# FM33L0XX register map
File version: 1.0
CPU: SC000 r1p0, little endian, no MPU, no FPU, 3 interrupt priority bits
Registers are 32-bit, read-write, reset 0x0 unless marked. A register's access mark holds for its fields unless they carry their own. Offsets are from the block's base; [hi:lo] are bit positions; {n}, {i} and the like mark numbered series.

## LCD — LCD Registers
Base 0x40010C00
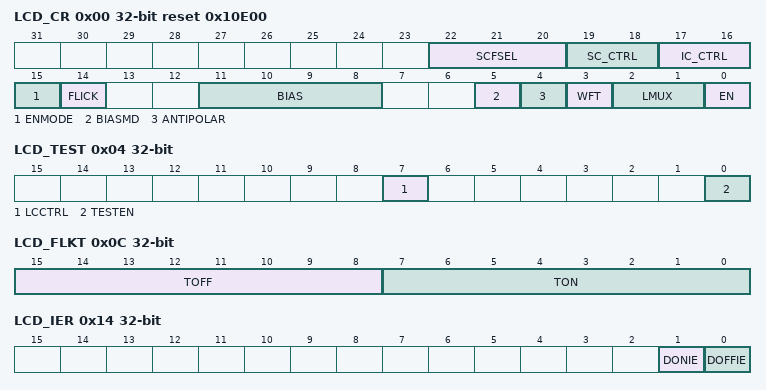
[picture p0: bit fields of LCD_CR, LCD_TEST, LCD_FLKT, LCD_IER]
0x00 LCD_CR reset 0x10E00 — LCD Control Register
  [22:20] SCFSEL
    0=FRAME*COM; 0=disp_clk/8; 0=disp_clk/16; 0=disp_clk/32; 0=disp_clk/64; 0=disp_clk/128; 0=disp_clk/256; 0=disp_clk/512
  [19:18] SC_CTRL
    0=DRIVE ONE; 1=DRIVE TWO; 2=DRIVE FOUR; 3=DRIVE MANY TIMES
  [17:16] IC_CTRL
    0=I_MAX; 1=I_SECONG_MAX; 2=I_SECONG_MIN; 3=I_MIN
  [15] ENMODE
    0=OUT CAP EN; 1=IN RES EN
  [14] FLICK
    0=DISABLE; 1=ENABLE
  [11:8] BIAS — LCDBIAS
  [5] BIASMD
    0=1/4 BIAS; 1=1/3 BIAS
  [4] ANTIPOLAR — COM & SEG C0ONNECT TO GND OR FLOATING AT DISP DISABLE
    0=FLOATING; 1=GND
  [3] WFT
    0=A; 1=B
  [2:1] LMUX
    0=4COM; 1=6COM; 2=8COM; 3=8COM
  [0] EN
    0=DISABLE; 1=ENABLE
0x04 LCD_TEST
  [7] LCCTRL — TEST CONTROL
  [0] TESTEN — EXTI1[0] input pin select
0x08 LCD_FCR — DIVIDED FREQ
  [7:0] DF
0x0C LCD_FLKT — FLICK TIME SETTING
  [15:8] TOFF — FLICK TIME SETTING
  [7:0] TON — FLICK TIME SETTING
0x14 LCD_IER — DISP IE
  [1] DONIE — DISPLAY ON IE
  [0] DOFFIE — DISPLAY OFF IE
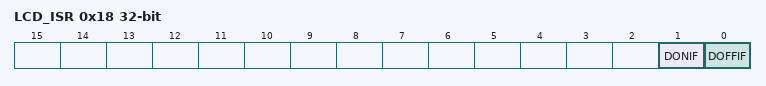
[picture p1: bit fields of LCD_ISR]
0x18 LCD_ISR — DISP IF
  [1] DONIF — DISP ON IF
  [0] DOFFIF — DISP OFF IF
{0x24+4i} LCD_DATA{i} (i=0..7) — DISPLAY DATA REGISTER
0x50 LCD_COM_EN — COM ENABLE
  [3:0] COMEN — COMEN 0-3
0x54 LCDSEG_EN0 — SEG ENABLE
  [31:0] SEGEN

## RTC — RTC Registers
Base 0x40011000
0x00 RTC_WER — RTC WRITE PROTECT REGISTER
  [0] WE — RTCWE
    0=DISABLE; 1=ENABLE
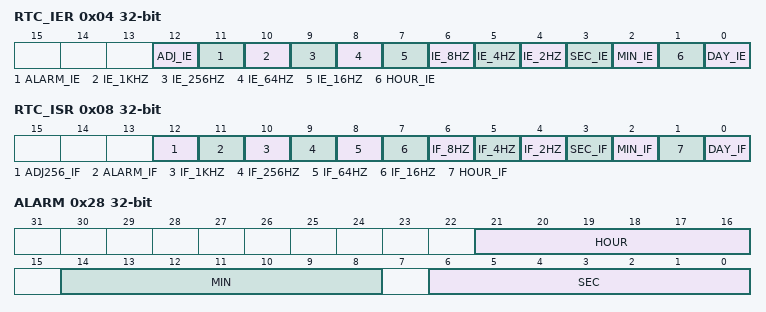
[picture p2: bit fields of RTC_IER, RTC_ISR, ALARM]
0x04 RTC_IER — RTC IE
  [12] ADJ_IE, [11] ALARM_IE, [10] IE_1KHZ, [9] IE_256HZ, [8] IE_64HZ, [7] IE_16HZ, [6] IE_8HZ, [5] IE_4HZ, [4] IE_2HZ, [3] SEC_IE, [2] MIN_IE, [1] HOUR_IE, [0] DAY_IE
0x08 RTC_ISR — RTC IF
  [12] ADJ256_IF, [11] ALARM_IF, [10] IF_1KHZ, [9] IF_256HZ, [8] IF_64HZ, [7] IF_16HZ, [6] IF_8HZ, [5] IF_4HZ, [4] IF_2HZ, [3] SEC_IF, [2] MIN_IF, [1] HOUR_IF, [0] DAY_IF
0x0C RTC_BCDSEC — SECOND REGISTER IN BCD
  [6:0] SEC — SECOND IN BCD
0x10 RTC_BCDMIN — MINUTE REGISTER IN BCD
  [6:0] MIN — MINUTE IN BCD
0x14 RTC_BCDHOUR — HOUR REGISTER IN BCD
  [5:0] HOUR — HOUR IN BCD
0x18 RTC_BCDDAY — DAY REGISTER IN BCD
  [5:0] DAY — DAY IN BCD
0x1C RTC_BCDWEEK — WEEK REGISTER IN BCD
  [2:0] WEEK — WEEK IN BCD
0x20 RTC_BCDMONTH — MONTH REGISTER IN BCD
  [4:0] MONTH — MONTH IN BCD
0x24 RTC_BCDYEAR — YEAR REGISTER IN BCD
  [7:0] YEAR — YEAR IN BCD
0x28 ALARM — ALARM SETTING REGISTER
  [21:16] HOUR — ALARM HOUR SETTING
  [14:8] MIN — ALARM MINUTE SETTING
  [6:0] SEC — ALARM SECOND SETTING
0x2C RTC_TMSEL — FREQ SIGNAL OUTPUT SELECT
  [3:0] TMSEL
    2=SEC_CARRY (SECOND CARRY SIGNAL); 3=MIN_CARRY (MINUTE CARRY SIGNAL); 4=HOUR_CARRY (HOUR CARRY SIGNAL); 5=DATE_CARRY (DATE CARRY SIGNAL); 6=ALARM_SIG (ALARM SIGNAL); 7=32S_SIG; 9=REV_SEC_CARRY (REVERSE SEC_CARRY); 10=REV_MIN_CARRY (REVERSE MINUTE CARRY SIGNAL); 11=REV_HOUR_CARRY (REVERSE HOUR CARRY SIGNAL); 12=REV_DATE_CARRY (REVERSE DATE CARRY SIGNAL); 13=REV_ALARM (REVERSE ALARM SIGNAL); 15=INNER_SEC (INNER SECOND SIGNAL)
0x30 RTC_DJUST — LTBC ADJUST register
  [8:0] ADJUST — LTBC ADJUST
0x34 RTC_ADSIGN — LTBC ADJUST SIGN REGISTER
  [0] ADSIGN — LTBC ADJUST SIGN
    0=ADD; 1=DECREASE
0x3C RTC_SBSCNT — MS COUNTER register
  [7:0] MSCNT — MS COUNTER
{0x70+4i} RTCBKR{i} (i=0..7)
  [31:0] BKR0

## IWDT
Base 0x40011400
0x00 IWDT_SERV wo — IWDT SERVER
  [31:0] SERV — wdtserv
0x04 IWDT_CR reset 0x2 — IWDT CONFIG REGISTER
  [2:0] CFG — IWDT overflow period setting
    0=125MS; 1=250MS; 2=500MS; 3=1S; 4=2S; 5=4S; 6=8S; 7=16S
0x08 IWDT_CNT ro — iwdt counter register
  [11:0] TCNT rw — IWDTCNT counter
0x0C IWDT_WIN
  [11:0] WIN
0x10 IWDT_SR
  [0] BUSY ro — Iwdtbusy
    0=no clear dog; 1=clear dog

## WWDT — WWDT Registers
Base 0x40011800
0x00 WWDT_CR wo — WWDT CONTROL REGISTER
0x04 WWDT_CFGR — WWDT CONFIG REGISTER
  [2:0] WWDT_CFG — WWDT CONFIG
    0=1T (TPCLK*4096*1); 1=4T (TPCLK*4096*4); 2=16T (TPCLK*4096*16); 3=64T (TPCLK*4096*64); 4=128T (TPCLK*4096*128); 5=256T (TPCLK*4096*256); 6=512T (TPCLK*4096*512); 7=1024T (TPCLK*4096*1024)
0x08 WWDT_CNT — WWDT COUNTER REGISTER
  [9:0] CNT ro — WWDT COUNTER
0x0C WWDT_IER — WWDT IE
  [0] IE
0x10 WWDT_ISR — WWDT IF
  [0] if
0x14 WWDT_PSC — WWDTDIV
  [11:0] DIV_CNT ro
